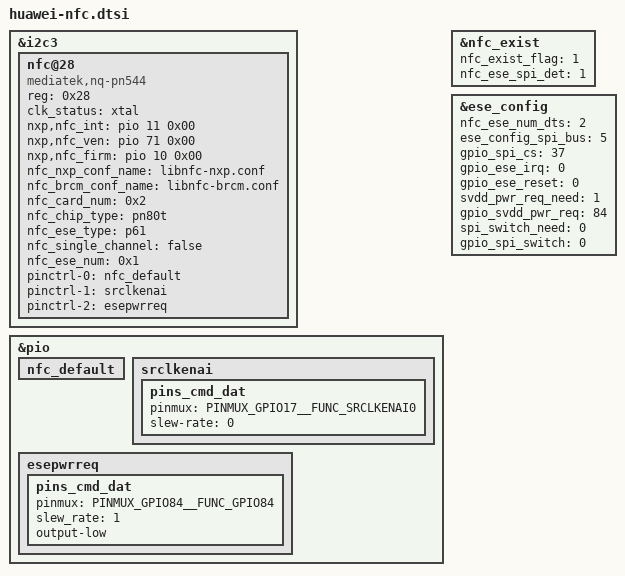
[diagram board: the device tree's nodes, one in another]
&i2c3 {
	nfc@28 {
        #address-cells = <1>;
        #size-cells = <0>;
		compatible = "mediatek,nq-pn544";
		status = "okay";
		reg = <0x28>;
		clk_status ="xtal";
		nxp,nfc_int = <&pio 11 0x00>;
		nxp,nfc_ven = <&pio 71 0x00>;
		nxp,nfc_firm = <&pio 10 0x00>;
		nfc_nxp_conf_name = "libnfc-nxp.conf";
		nfc_brcm_conf_name = "libnfc-brcm.conf";
		nfc_card_num = <0x2>;
		nfc_chip_type = "pn80t";
		nfc_ese_type = "p61";
		nfc_single_channel = "false";
		nfc_ese_num = <0x1>;
		pinctrl-names = "nfc_default","srclkenai","esepwrreq";
		pinctrl-0 = <&nfc_default>;
		pinctrl-1 = <&srclkenai>;
		pinctrl-2 = <&esepwrreq>;
	};
};

&pio {
	nfc_default: nfc_default {
	};

	srclkenai: srclkenai {
		pins_cmd_dat {
			pinmux = <PINMUX_GPIO17__FUNC_SRCLKENAI0>;
			slew-rate = <0>;
		};
	};
	esepwrreq: esepwrreq {
		pins_cmd_dat {
			pinmux = <PINMUX_GPIO84__FUNC_GPIO84>;
			slew_rate = <1>;
			output-low;
		};
	};
};

&nfc_exist {
	nfc_exist_flag = "1";
	nfc_ese_spi_det = "1";
	status = "ok";
};

&ese_config {
	nfc_ese_num_dts = <2>;
	ese_config_spi_bus = <5>;
	gpio_spi_cs = <37>;
	gpio_ese_irq = <0>;
	gpio_ese_reset = <0>;
	svdd_pwr_req_need = <1>;
	gpio_svdd_pwr_req = <84>;
	spi_switch_need = <0>;
	gpio_spi_switch = <0>;
	status = "ok";
};
